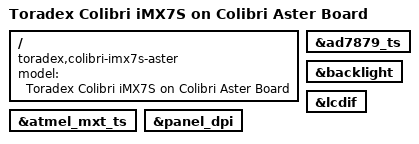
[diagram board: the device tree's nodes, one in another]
/*
 * Copyright 2017 Toradex AG
 *
 * This program is free software; you can redistribute it and/or modify
 * it under the terms of the GNU General Public License as published by
 * the Free Software Foundation; either version 2 of the License, or
 * (at your option) any later version.
 */

/dts-v1/;
#include "imx7s-colibri.dtsi"
#include "imx7-colibri-aster.dtsi"

/ {
	model = "Toradex Colibri iMX7S on Colibri Aster Board";
	compatible = "toradex,colibri-imx7s-aster",
		     "toradex,colibri-imx7s",
		     "fsl,imx7s", "fsl,imx7d";
};

&ad7879_ts {
	status = "okay";
};

&atmel_mxt_ts {
	status = "okay";
};

&backlight {
	status = "okay";
};

&lcdif {
	status = "okay";
};

&panel_dpi {
	status = "okay";
};
